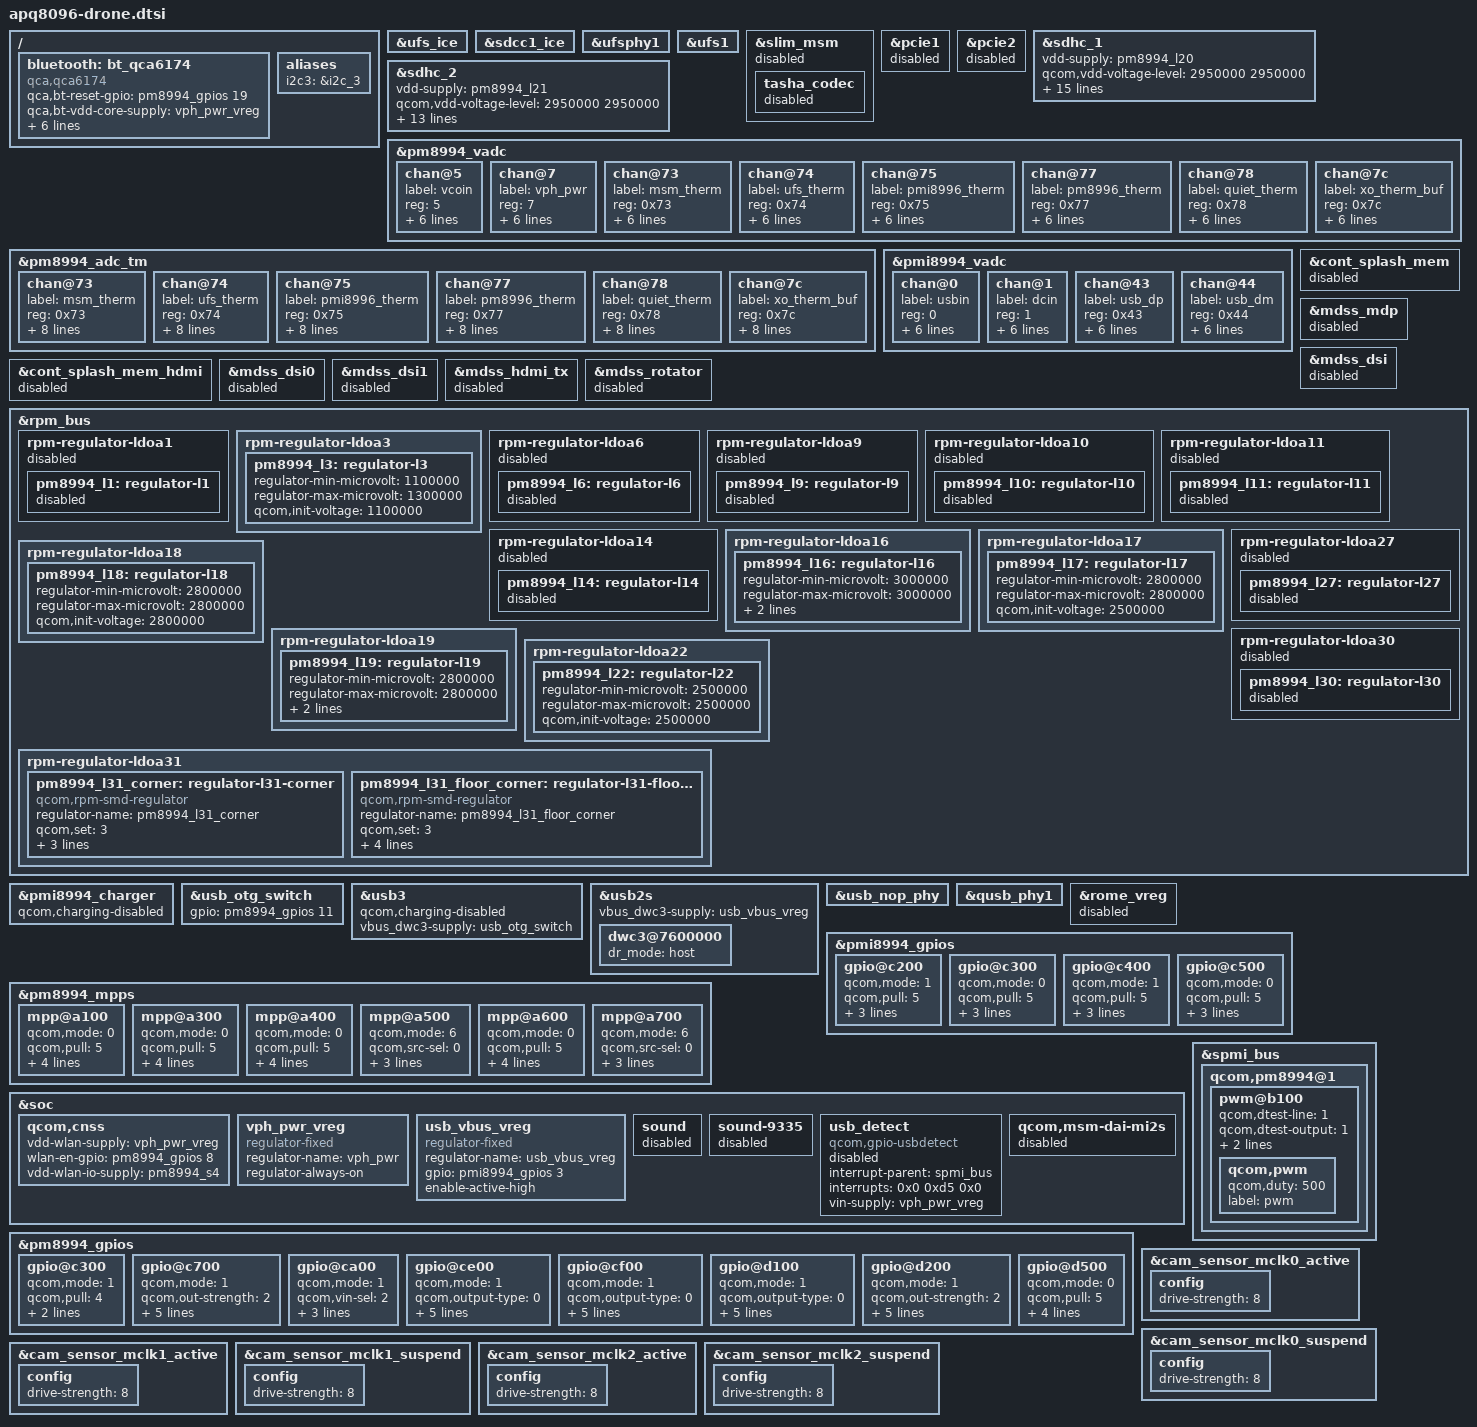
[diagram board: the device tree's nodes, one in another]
/* Copyright (c) 2016-2017, The Linux Foundation. All rights reserved.
 *
 * This program is free software; you can redistribute it and/or modify
 * it under the terms of the GNU General Public License version 2 and
 * only version 2 as published by the Free Software Foundation.
 *
 * This program is distributed in the hope that it will be useful,
 * but WITHOUT ANY WARRANTY; without even the implied warranty of
 * MERCHANTABILITY or FITNESS FOR A PARTICULAR PURPOSE.  See the
 * GNU General Public License for more details.
 */

#include "msm8996-pinctrl.dtsi"
#include "apq8096-camera-sensor-drone.dtsi"
#include "msm-pmi8996.dtsi"
#include "apq8096-drone-sensors.dtsi"

/ {
	bluetooth: bt_qca6174 {
		compatible = "qca,qca6174";
		qca,bt-reset-gpio = <&pm8994_gpios 19 0>; /* BT_EN */
		qca,bt-vdd-core-supply = <&vph_pwr_vreg>;
		qca,bt-vdd-pa-supply = <&vph_pwr_vreg>;
		qca,bt-vdd-io-supply = <&pm8994_s4>;
		qca,bt-vdd-xtal-supply = <&vph_pwr_vreg>;
		qca,bt-chip-pwd-voltage-level = <1300000 1300000>;
		qca,bt-vdd-io-voltage-level = <1800000 1800000>;
		qca,bt-vdd-xtal-voltage-level = <1800000 1800000>;
	};
	aliases {
		i2c3 = &i2c_3;
	};
};

&ufs_ice {
	status = "ok";
};

&sdcc1_ice {
	status = "ok";
};

&ufsphy1 {
	status = "ok";
};

&ufs1 {
	status = "ok";
	/delete-property/ vccq-supply;
	/delete-property/ vccq-max-microamp;
};

&slim_msm {
	status = "disabled"; /* disable GPIO60 + 61, 64 */
	tasha_codec {
		status = "disabled"; /* disable GPIO60 + 61, 64 */
	};
};

&pcie1 {
	status = "disabled";
};

&pcie2 {
	status = "disabled";
};

&sdhc_1 {
	vdd-supply = <&pm8994_l20>;
	qcom,vdd-voltage-level = <2950000 2950000>;
	qcom,vdd-current-level = <200 570000>;

	vdd-io-supply = <&pm8994_s4>;
	qcom,vdd-io-always-on;
	qcom,vdd-io-voltage-level = <1800000 1800000>;
	qcom,vdd-io-current-level = <110 325000>;

	pinctrl-names = "active", "sleep";
	pinctrl-0 = <&sdc1_clk_on &sdc1_cmd_on &sdc1_data_on &sdc1_rclk_on>;
	pinctrl-1 = <&sdc1_clk_off &sdc1_cmd_off &sdc1_data_off &sdc1_rclk_off>;

	qcom,clk-rates = <400000 20000000 25000000 50000000
				96000000 192000000 384000000>;
	qcom,ice-clk-rates = <300000000 150000000>;
	qcom,nonremovable;
	qcom,bus-speed-mode = "HS400_1p8v", "HS200_1p8v", "DDR_1p8v";

	status = "ok";
};

&sdhc_2 {
	vdd-supply = <&pm8994_l21>;
	qcom,vdd-voltage-level = <2950000 2950000>;
	qcom,vdd-current-level = <200 800000>;

	vdd-io-supply = <&pm8994_l13>;
	qcom,vdd-io-voltage-level = <1800000 2950000>;
	qcom,vdd-io-current-level = <200 22000>;

	pinctrl-names = "active", "sleep";
	pinctrl-0 = <&sdc2_clk_on  &sdc2_cmd_on
				&sdc2_data_on &sdc2_cd_on_sbc>;
	pinctrl-1 = <&sdc2_clk_off &sdc2_cmd_off
				&sdc2_data_off &sdc2_cd_off_sbc>;

	qcom,clk-rates = <400000 20000000 25000000 50000000
				100000000 200000000>;
	qcom,bus-speed-mode = "SDR12", "SDR25", "SDR50", "DDR50", "SDR104";

	cd-gpios = <&tlmm 38 0x1>;

	status = "ok";
};

&pm8994_vadc {
	chan@5 {
		label = "vcoin";
		reg = <5>;
		qcom,decimation = <0>;
		qcom,pre-div-channel-scaling = <1>;
		qcom,calibration-type = "absolute";
		qcom,scale-function = <0>;
		qcom,hw-settle-time = <0>;
		qcom,fast-avg-setup = <0>;
	};

	chan@7 {
		label = "vph_pwr";
		reg = <7>;
		qcom,decimation = <0>;
		qcom,pre-div-channel-scaling = <1>;
		qcom,calibration-type = "absolute";
		qcom,scale-function = <0>;
		qcom,hw-settle-time = <0>;
		qcom,fast-avg-setup = <0>;
	};

	chan@73 {
		label = "msm_therm";
		reg = <0x73>;
		qcom,decimation = <0>;
		qcom,pre-div-channel-scaling = <0>;
		qcom,calibration-type = "ratiometric";
		qcom,scale-function = <2>;
		qcom,hw-settle-time = <2>;
		qcom,fast-avg-setup = <0>;
	};

	chan@74 {
		label = "ufs_therm";
		reg = <0x74>;
		qcom,decimation = <0>;
		qcom,pre-div-channel-scaling = <0>;
		qcom,calibration-type = "ratiometric";
		qcom,scale-function = <2>;
		qcom,hw-settle-time = <2>;
		qcom,fast-avg-setup = <0>;
	};

	chan@75 {
		label = "pmi8996_therm";
		reg = <0x75>;
		qcom,decimation = <0>;
		qcom,pre-div-channel-scaling = <0>;
		qcom,calibration-type = "ratiometric";
		qcom,scale-function = <2>;
		qcom,hw-settle-time = <2>;
		qcom,fast-avg-setup = <0>;
	};

	chan@77 {
		label = "pm8996_therm";
		reg = <0x77>;
		qcom,decimation = <0>;
		qcom,pre-div-channel-scaling = <0>;
		qcom,calibration-type = "ratiometric";
		qcom,scale-function = <2>;
		qcom,hw-settle-time = <2>;
		qcom,fast-avg-setup = <0>;
	};

	chan@78 {
		label = "quiet_therm";
		reg = <0x78>;
		qcom,decimation = <0>;
		qcom,pre-div-channel-scaling = <0>;
		qcom,calibration-type = "ratiometric";
		qcom,scale-function = <2>;
		qcom,hw-settle-time = <2>;
		qcom,fast-avg-setup = <0>;
	};

	chan@7c {
		label = "xo_therm_buf";
		reg = <0x7c>;
		qcom,decimation = <0>;
		qcom,pre-div-channel-scaling = <0>;
		qcom,calibration-type = "ratiometric";
		qcom,scale-function = <4>;
		qcom,hw-settle-time = <2>;
		qcom,fast-avg-setup = <0>;
	};
};

&pm8994_adc_tm {
	chan@73 {
		label = "msm_therm";
		reg = <0x73>;
		qcom,decimation = <0>;
		qcom,pre-div-channel-scaling = <0>;
		qcom,calibration-type = "ratiometric";
		qcom,scale-function = <2>;
		qcom,hw-settle-time = <2>;
		qcom,fast-avg-setup = <0>;
		qcom,btm-channel-number = <0x48>;
		qcom,thermal-node;
	};

	chan@74 {
		label = "ufs_therm";
		reg = <0x74>;
		qcom,decimation = <0>;
		qcom,pre-div-channel-scaling = <0>;
		qcom,calibration-type = "ratiometric";
		qcom,scale-function = <2>;
		qcom,hw-settle-time = <2>;
		qcom,fast-avg-setup = <0>;
		qcom,btm-channel-number = <0x68>;
		qcom,thermal-node;
	};

	chan@75 {
		label = "pmi8996_therm";
		reg = <0x75>;
		qcom,decimation = <0>;
		qcom,pre-div-channel-scaling = <0>;
		qcom,calibration-type = "ratiometric";
		qcom,scale-function = <2>;
		qcom,hw-settle-time = <2>;
		qcom,fast-avg-setup = <0>;
		qcom,btm-channel-number = <0x70>;
		qcom,thermal-node;
	};

	chan@77 {
		label = "pm8996_therm";
		reg = <0x77>;
		qcom,decimation = <0>;
		qcom,pre-div-channel-scaling = <0>;
		qcom,calibration-type = "ratiometric";
		qcom,scale-function = <2>;
		qcom,hw-settle-time = <2>;
		qcom,fast-avg-setup = <0>;
		qcom,btm-channel-number = <0x78>;
		qcom,thermal-node;
	};

	chan@78 {
		label = "quiet_therm";
		reg = <0x78>;
		qcom,decimation = <0>;
		qcom,pre-div-channel-scaling = <0>;
		qcom,calibration-type = "ratiometric";
		qcom,scale-function = <2>;
		qcom,hw-settle-time = <2>;
		qcom,fast-avg-setup = <0>;
		qcom,btm-channel-number = <0x80>;
		qcom,thermal-node;
	};

	chan@7c {
		label = "xo_therm_buf";
		reg = <0x7c>;
		qcom,decimation = <0>;
		qcom,pre-div-channel-scaling = <0>;
		qcom,calibration-type = "ratiometric";
		qcom,scale-function = <4>;
		qcom,hw-settle-time = <2>;
		qcom,fast-avg-setup = <0>;
		qcom,btm-channel-number = <0x88>;
		qcom,thermal-node;
	};
};

&pmi8994_vadc {
	chan@0 {
		label = "usbin";
		reg = <0>;
		qcom,decimation = <0>;
		qcom,pre-div-channel-scaling = <4>;
		qcom,calibration-type = "absolute";
		qcom,scale-function = <0>;
		qcom,hw-settle-time = <0>;
		qcom,fast-avg-setup = <0>;
	};

	chan@1 {
		label = "dcin";
		reg = <1>;
		qcom,decimation = <0>;
		qcom,pre-div-channel-scaling = <4>;
		qcom,calibration-type = "absolute";
		qcom,scale-function = <0>;
		qcom,hw-settle-time = <0>;
		qcom,fast-avg-setup = <0>;
	};

	chan@43 {
		label = "usb_dp";
		reg = <0x43>;
		qcom,decimation = <0>;
		qcom,pre-div-channel-scaling = <1>;
		qcom,calibration-type = "absolute";
		qcom,scale-function = <0>;
		qcom,hw-settle-time = <0>;
		qcom,fast-avg-setup = <0>;
	};

	chan@44 {
		label = "usb_dm";
		reg = <0x44>;
		qcom,decimation = <0>;
		qcom,pre-div-channel-scaling = <1>;
		qcom,calibration-type = "absolute";
		qcom,scale-function = <0>;
		qcom,hw-settle-time = <0>;
		qcom,fast-avg-setup = <0>;
	};
};

&cont_splash_mem {
	status = "disabled";
};

&cont_splash_mem_hdmi {
	status = "disabled";
};

&mdss_mdp {
	status = "disabled";
};

&mdss_dsi {
	status = "disabled";
};

&mdss_dsi0 {
	status = "disabled";
};

&mdss_dsi1 {
	status = "disabled";
};

&mdss_hdmi_tx {
	status = "disabled";
};

&mdss_rotator {
	status = "disabled";
};


&rpm_bus {
	rpm-regulator-ldoa1 {
		status = "disabled";
		pm8994_l1: regulator-l1 {
			status = "disabled";
		};
	};

	rpm-regulator-ldoa3 {
		status = "okay";
		pm8994_l3: regulator-l3 {
			regulator-min-microvolt = <1100000>;
			regulator-max-microvolt = <1300000>;
			qcom,init-voltage = <1100000>;
			status = "okay";
		};
	};

	rpm-regulator-ldoa6 {
		status = "disabled";
		pm8994_l6: regulator-l6 {
			status = "disabled";
		};
	};

	rpm-regulator-ldoa9 {
		status = "disabled";
		pm8994_l9: regulator-l9 {
			status = "disabled";
		};
	};

	rpm-regulator-ldoa10 {
		status = "disabled";
		pm8994_l10: regulator-l10 {
			status = "disabled";
		};
	};

	rpm-regulator-ldoa11 {
		status = "disabled";
		pm8994_l11: regulator-l11 {
			status = "disabled";
		};
	};

	rpm-regulator-ldoa14 {
		status = "disabled";
		pm8994_l14: regulator-l14 {
			status = "disabled";
		};
	};

	rpm-regulator-ldoa16 {
		status = "okay";
		pm8994_l16: regulator-l16 {
			regulator-min-microvolt = <3000000>;
			regulator-max-microvolt = <3000000>;
			qcom,init-voltage = <3000000>;
			status = "okay";
		};
	};

	rpm-regulator-ldoa17 {
		status = "okay";
		pm8994_l17: regulator-l17 {
			regulator-min-microvolt = <2800000>;
			regulator-max-microvolt = <2800000>;
			qcom,init-voltage = <2500000>;
			status = "okay";
		};
	};

	rpm-regulator-ldoa18 {
		status = "okay";
		pm8994_l18: regulator-l18 {
			regulator-min-microvolt = <2800000>;
			regulator-max-microvolt = <2800000>;
			qcom,init-voltage = <2800000>;
			status = "okay";
		};
	};

	rpm-regulator-ldoa19 {
		status = "okay";
		pm8994_l19: regulator-l19 {
			regulator-min-microvolt = <2800000>;
			regulator-max-microvolt = <2800000>;
			qcom,init-voltage = <2800000>;
			status = "okay";
		};
	};

	rpm-regulator-ldoa22 {
		status = "okay";
		pm8994_l22: regulator-l22 {
			regulator-min-microvolt = <2500000>;
			regulator-max-microvolt = <2500000>;
			qcom,init-voltage = <2500000>;
			status = "okay";
		};
	};

	rpm-regulator-ldoa27 {
		status = "disabled";
		pm8994_l27: regulator-l27 {
			status = "disabled";
		};
	};

	rpm-regulator-ldoa30 {
		status = "disabled";
		pm8994_l30: regulator-l30 {
			status = "disabled";
		};
	};

	rpm-regulator-ldoa31 {
		status = "okay";
		pm8994_l31_corner: regulator-l31-corner {
			compatible = "qcom,rpm-smd-regulator";
			regulator-name = "pm8994_l31_corner";
			qcom,set = <3>;
			regulator-min-microvolt = <1>;
			regulator-max-microvolt = <7>;
			qcom,use-voltage-corner;
		};

		pm8994_l31_floor_corner: regulator-l31-floor-corner {
			compatible = "qcom,rpm-smd-regulator";
			regulator-name = "pm8994_l31_floor_corner";
			qcom,set = <3>;
			regulator-min-microvolt = <1>;
			regulator-max-microvolt = <7>;
			qcom,use-voltage-floor-corner;
			qcom,always-send-voltage;
		};
	};
};

&pmi8994_charger {
	qcom,charging-disabled;
};

&usb_otg_switch {
	gpio = <&pm8994_gpios 11 0>;
	status = "ok";
};

&usb3 {
	qcom,charging-disabled;
	vbus_dwc3-supply = <&usb_otg_switch>;
};

&usb2s {
	status = "ok";
	vbus_dwc3-supply = <&usb_vbus_vreg>;
	dwc3@7600000 {
		dr_mode = "host";
	};
};

&usb_nop_phy {
	status = "ok";
};

&qusb_phy1 {
	status = "ok";
};

&rome_vreg {
	status = "disabled";
};

&pm8994_l16 { /* GPS ELNA */
	status = "okay";
	regulator-always-on;
};

&pm8994_l19 { /* Barometer and IMUs */
	status = "okay";
	regulator-always-on;
};

&pm8994_mpps {
	mpp@a100 { /* MPP 2 - TP82 */
		qcom,mode = <0>;		/* Digital input */
		qcom,pull = <5>;		/* Pull down */
		qcom,vin-sel = <2>;		/* S4 1.8V */
		qcom,src-sel = <0>;		/* Constant */
		qcom,master-en = <1>;		/* Enable GPIO */
		qcom,invert = <0>;
		status = "okay";
	};

	mpp@a300 { /* MPP 4 - FAN_DETECT */
		qcom,mode = <0>;		/* Digital input */
		qcom,pull = <5>;		/* Pull down */
		qcom,vin-sel = <2>;		/* S4 1.8V */
		qcom,src-sel = <0>;		/* Constant */
		qcom,master-en = <1>;		/* Enable GPIO */
		qcom,invert = <0>;
		status = "okay";
	};

	mpp@a400 { /* MPP 5 - TP81 */
		qcom,mode = <0>;		/* Digital input */
		qcom,pull = <5>;		/* Pull down */
		qcom,vin-sel = <2>;		/* S4 1.8V */
		qcom,src-sel = <0>;		/* Constant */
		qcom,master-en = <1>;		/* Enable GPIO */
		qcom,invert = <0>;
		status = "okay";
	};

	mpp@a500 { /* MPP 6 - RED LED */
		qcom,mode = <6>;		/* Sink */
		qcom,src-sel = <0>;		/* Constant */
		qcom,cs-out = <3>;      /* 20 MA */
		qcom,master-en = <1>;		/* Enable GPIO */
		qcom,invert = <1>;
		status = "okay";
	};

	mpp@a600 { /* MPP 7 - TP83 */
		qcom,mode = <0>;		/* Digital input */
		qcom,pull = <5>;		/* Pull down */
		qcom,vin-sel = <2>;		/* S4 1.8V */
		qcom,src-sel = <0>;		/* Constant */
		qcom,master-en = <1>;		/* Enable GPIO */
		qcom,invert = <0>;
		status = "okay";
	};

	mpp@a700 { /* MPP 8 - GREEN LED */
		qcom,mode = <6>;		/* Sink */
		qcom,src-sel = <0>;		/* Constant */
		qcom,cs-out = <3>;      /* 20 MA */
		qcom,master-en = <1>;		/* Enable GPIO */
		qcom,invert = <1>;
		status = "okay";
	};
};

&pmi8994_gpios {
	gpio@c200 {	/* GPIO 3 USB2_HS_VBUS_EN */
		qcom,mode = <1>;	/* DIGITAL OUT */
		qcom,pull = <5>;	/* No Pull */
		qcom,vin-sel = <2>;	/* 1.8 */
		qcom,src-sel = <0>;	/* CONSTANT */
		qcom,master-en = <1>;	/* ENABLE GPIO */
		status = "okay";
	};

	gpio@c300 {	/* GPIO 4 USB2_HS_ID */
		qcom,mode = <0>;	/* DIGITAL INPUT */
		qcom,pull = <5>;	/* No Pull */
		qcom,vin-sel = <2>;	/* 1.8 */
		qcom,src-sel = <0>;	/* CONSTANT */
		qcom,master-en = <1>;	/* ENABLE GPIO */
		status = "okay";
	};

	gpio@c400 {	/* GPIO 5 USB1_HS_VBUS_EN */
		qcom,mode = <1>;	/* DIGITAL OUT */
		qcom,pull = <5>;	/* No Pull */
		qcom,vin-sel = <2>;	/* 1.8 */
		qcom,src-sel = <0>;	/* CONSTANT */
		qcom,master-en = <1>;	/* ENABLE GPIO */
		status = "okay";
	};

	gpio@c500 {	/* GPIO 6 USB2_HS_VBUS_DET*/
		qcom,mode = <0>;	/* DIGITAL INPUT */
		qcom,pull = <5>;	/* No Pull */
		qcom,vin-sel = <2>;	/* 1.8 */
		qcom,src-sel = <0>;	/* CONSTANT */
		qcom,master-en = <1>;	/* ENABLE GPIO */
		status = "okay";
	};
};

&soc {
	qcom,cnss {
		vdd-wlan-supply = <&vph_pwr_vreg>;
		wlan-en-gpio = <&pm8994_gpios 8 0>;
		vdd-wlan-io-supply = <&pm8994_s4>;
		// removing unneeded regulators
		/delete-property/ vdd-wlan-xtal-supply;
		/delete-property/ vdd-wlan-core-supply;
		/delete-property/ wlan-ant-switch-supply;
		/delete-property/ wlan-bootstrap-gpio;
	};

	/*
	* vph_pwr_vreg represents the unregulated battery voltage supply
	* VPH_PWR that is present whenever the device is powered on.
	*/
	vph_pwr_vreg: vph_pwr_vreg {
		compatible = "regulator-fixed";
		regulator-name = "vph_pwr";
		status = "ok";
		regulator-always-on;
	};

	usb_vbus_vreg: usb_vbus_vreg {
		compatible = "regulator-fixed";
		regulator-name = "usb_vbus_vreg";
		gpio = <&pmi8994_gpios 3 0>;
		enable-active-high;
	};

	sound {
		status = "disabled";
	};

	sound-9335 {
		status = "disabled";
	};

	usb_detect {
		compatible = "qcom,gpio-usbdetect";
		interrupt-parent = <&spmi_bus>;
		interrupts = <0x0 0xd5 0x0>;  /* PM8994 GPIO22 */
		interrupt-names = "vbus_det_irq";
		vin-supply = <&vph_pwr_vreg>;
		status = "disabled";
	};

	qcom,msm-dai-mi2s {
		status = "disabled";
	};

};

&spmi_bus {
	qcom,pm8994@1 {
		pwm@b100 { /* Enable for FAN_PWM */
			qcom,dtest-line = <1>;
			qcom,dtest-output = <1>; /* Output to DTEST1 enabled */
			qcom,period = <500>;
			qcom,mode-select = <0>;
			status = "okay";
			qcom,pwm {
				qcom,duty = <500>;
				label = "pwm";
			};
		};
	};
};

&pm8994_gpios {

	gpio@c300 { /* GPIO 4 - FAN_PWM_OUT */
		qcom,mode = <1>;  // digital out
		qcom,pull = <4>; // pull down
		qcom,vin-sel = <2>;
		qcom,src-sel = <4>; // 4 = DTEST 1
		status = "okay";
	};

	gpio@c700 { /* GPIO 8 - WLAN_EN */
		qcom,mode = <1>;	/* Digital output*/
		qcom,out-strength = <2>; /* QPNP_PIN_OUT_STRENGTH_MED */
		qcom,pull = <4>;	/* Pulldown 10uA */
		qcom,vin-sel = <2>;	/* VIN2 */
		qcom,src-sel = <0>;	/* GPIO */
		qcom,invert = <0>;	/* Invert */
		qcom,master-en = <1>;	/* Enable GPIO */
		status = "okay";
	};

	gpio@ca00 { /* GPIO 11 - USB enb1 (otg switch) */
		qcom,mode = <1>;	/* DIGITAL OUT */
		qcom,vin-sel = <2>;	/* 1.8 */
		qcom,src-sel = <0>;	/* GPIO */
		qcom,master-en = <1>;	/* Enable GPIO */
		qcom,invert = <0>;	/* Invert */
		status = "okay";
	};

	gpio@ce00 { /* GPIO 15 - DIVCLK1, goes to base board */
		qcom,mode = <1>;
		qcom,output-type = <0>;
		qcom,pull = <5>;
		qcom,vin-sel = <2>;
		qcom,out-strength = <1>;
		qcom,src-sel = <2>;
		qcom,master-en = <1>;
		status = "okay";
	};

	gpio@cf00 { /* GPIO 16 - DIVCLK2 - to PMI chip */
		qcom,mode = <1>;
		qcom,output-type = <0>;
		qcom,pull = <5>;
		qcom,vin-sel = <2>;
		qcom,out-strength = <1>;
		qcom,src-sel = <2>;
		qcom,master-en = <1>;
		status = "okay";
	};

	gpio@d100 { /* GPIO 17 - DIVCLK4 - to QCA6174 */
		qcom,mode = <1>;
		qcom,output-type = <0>;
		qcom,pull = <5>;
		qcom,vin-sel = <2>;
		qcom,out-strength = <1>;
		qcom,src-sel = <2>;
		qcom,master-en = <1>;
		status = "okay";
	};

	gpio@d200 { /* GPIO 19 - Rome BT Reset */
		qcom,mode = <1>;		/* Digital output*/
		qcom,out-strength = <2>;	/* QPNP_PIN_OUT_STRENGTH_MED */
		qcom,pull = <4>;		/* Pulldown 10uA */
		qcom,vin-sel = <2>;		/* VIN2 */
		qcom,src-sel = <0>;		/* GPIO */
		qcom,invert = <0>;		/* Invert */
		qcom,master-en = <1>;		/* Enable GPIO */
		status = "okay";
	};

	gpio@d500 { /* GPIO 22 - USB1 VBUS detect  */
		qcom,mode = <0>;		/* Digital Input*/
		qcom,pull = <5>;		/* No pull */
		qcom,vin-sel = <2>;		/* 1.8 V */
		qcom,src-sel = <0>;		/* GPIO */
		qcom,invert = <0>;		/* Invert */
		qcom,master-en = <1>;		/* Enable GPIO */
		status = "okay";
	};
};

&cam_sensor_mclk0_active { /* MCLK0 */
	config {
		drive-strength = <8>; /* 8 MA */
	};
};

&cam_sensor_mclk0_suspend { /* MCLK0 */
	config {
		drive-strength = <8>; /* 8 MA */
	};
};

&cam_sensor_mclk1_active { /* MCLK1 */
	config {
		drive-strength = <8>; /* 8 MA */
	};
};

&cam_sensor_mclk1_suspend { /* MCLK1 */
	config {
		drive-strength = <8>; /* 8 MA */
	};
};

&cam_sensor_mclk2_active { /* MCLK2 */
	config {
		drive-strength = <8>; /* 8 MA */
	};
};

&cam_sensor_mclk2_suspend { /* MCLK2 */
	config {
		drive-strength = <8>; /* 8 MA */
	};
};

